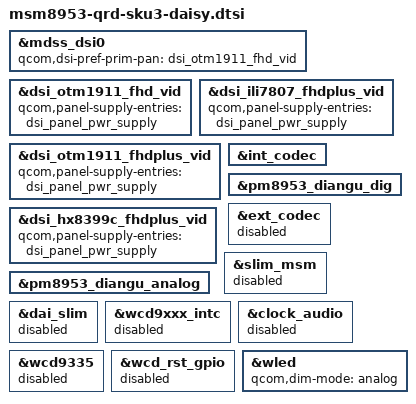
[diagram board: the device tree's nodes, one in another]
/*
 * Copyright (c) 2015-2016, The Linux Foundation. All rights reserved.
 * Copyright (C) 2018 XiaoMi, Inc.
 *
 * This program is free software; you can redistribute it and/or modify
 * it under the terms of the GNU General Public License version 2 and
 * only version 2 as published by the Free Software Foundation.
 *
 * This program is distributed in the hope that it will be useful,
 * but WITHOUT ANY WARRANTY; without even the implied warranty of
 * MERCHANTABILITY or FITNESS FOR A PARTICULAR PURPOSE.  See the
 * GNU General Public License for more details.
 */

#include "msm8953-qrd-daisy.dtsi"

#include "msm8953-mdss-panels-daisy.dtsi"

&mdss_dsi0 {
        qcom,dsi-pref-prim-pan = <&dsi_otm1911_fhd_vid>;
};

&dsi_otm1911_fhd_vid {
	qcom,panel-supply-entries = <&dsi_panel_pwr_supply>;

};

&dsi_ili7807_fhdplus_vid {
	qcom,panel-supply-entries = <&dsi_panel_pwr_supply>;

};

&dsi_otm1911_fhdplus_vid {
	qcom,panel-supply-entries = <&dsi_panel_pwr_supply>;

};

&dsi_hx8399c_fhdplus_vid {
	qcom,panel-supply-entries = <&dsi_panel_pwr_supply>;
};

&int_codec {
	status = "ok";
};

&pm8953_diangu_dig {
	status = "ok";
};

&pm8953_diangu_analog {
	status = "ok";
};

&ext_codec {
	status = "disabled";
};

&slim_msm {
	status = "disabled";
};

&dai_slim {
	status = "disabled";
};

&wcd9xxx_intc {
	status = "disabled";
};

&clock_audio {
	status = "disabled";
};

&wcd9335 {
	status = "disabled";
};

&wcd_rst_gpio {
	status = "disabled";
};

&wled {
	qcom,dim-mode = "analog";
};
